# BAT32A237 register map
Vendor: CMS; Series: BAT32A237; File version: 1.2
CPU: CM0+ r0p1, little endian, MPU, no FPU, VTOR, 2 interrupt priority bits
Registers are 8-bit, read-write, reset 0x0 unless marked. A register's access mark holds for its fields unless they carry their own. Offsets are from the block's base; [hi:lo] are bit positions; {n}, {i} and the like mark numbered series.

## MTB — Micro Trace Buffer
Base 0x40019000
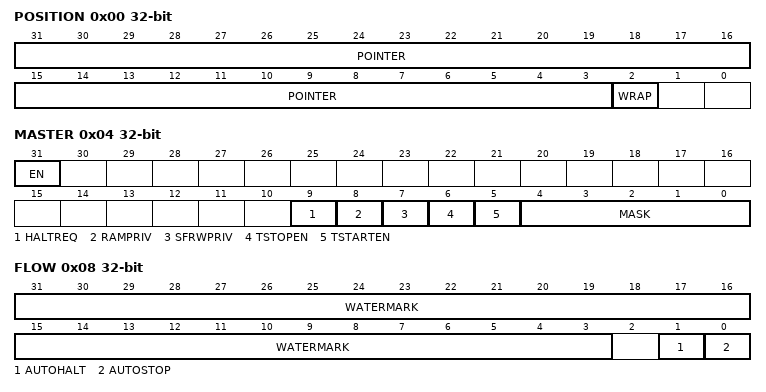
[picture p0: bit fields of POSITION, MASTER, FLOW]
0x00 POSITION 32-bit — MTB Position Register
  [31:3] POINTER, [2] WRAP
0x04 MASTER 32-bit — MTB Master Register
  [31] EN, [9] HALTREQ, [8] RAMPRIV, [7] SFRWPRIV, [6] TSTOPEN, [5] TSTARTEN, [4:0] MASK
0x08 FLOW 32-bit — MTB Flow Register
  [31:3] WATERMARK, [1] AUTOHALT, [0] AUTOSTOP
0x0C BASE 32-bit ro reset 0x20000000 — MTB Base Register
0xFB0 LOCKACCESS 32-bit — MTB Lock Access Register
0xFB4 LOCKSTATUS 32-bit ro — MTB Lock Status Register
0xFB8 AUTHSTATUS 32-bit ro reset 0xF — MTB Authentication Status Register
0xFBC DEVARCH 32-bit ro reset 0x47700A31 — MTB Device Architecture Register
0xFC8 DEVID 32-bit ro — MTB Device Configuration Register
0xFCC DEVTYPE 32-bit ro — MTB Device Type Register
{0xFC0+4i} PID{i} (i=4..7) 32-bit ro — CoreSight Register
{0xFE0+4i} PID{i} (i=0..3) 32-bit ro — CoreSight Register
{0xFF0+4i} CID{i} (i=0..3) 32-bit ro — CoreSight Register

## RST — Reset Function
Base 0x40020420
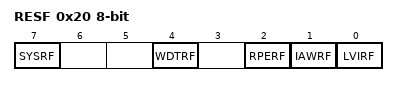
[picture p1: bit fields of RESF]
0x20 RESF ro — Reset flag register
  [all] fields
    0=NONE (Internal reset request is not generated, or the RESF register is cleared.); 1=DONE (Internal reset request is generated.)
  [7] SYSRF read-clears — Internal reset request by system reset request(AIRCR.SYSRESETREQ)
  [4] WDTRF read-clears — Internal reset request by watchdog timer(WDT)
  [2] RPERF read-clears — Internal reset request by RAM parity
  [1] IAWRF read-clears — Internal reset request by illegal-memory access
  [0] LVIRF read-clears — Internal reset request by voltage detector

## LVD — Voltage detector
Base 0x40020440
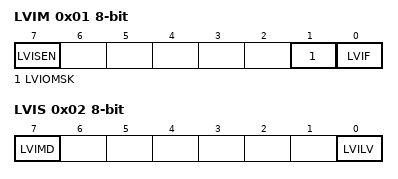
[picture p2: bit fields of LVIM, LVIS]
0x01 LVIM — Voltage detection register
  [7] LVISEN ro — Enable rewritting LVIS register
    0=Disable (Disabling of rewriting the LVIS register); 1=Enable (Enabling of rewriting the LVIS register)
  [1] LVIOMSK ro — Mask status flag of LVD output
    0=Invalid (Mask of LVD output is invalid); 1=Valid (Mask of LVD output is valid)
  [0] LVIF ro — Voltage detection flag
    0=GE (Supply voltage (VDD) greater or equal to detection voltage (VLVD), or when LVD is off); 1=LT (Supply voltage (VDD) less than detection voltage (VLVD))
0x02 LVIS — Voltage detection level register
  [7] LVIMD — Operation mode of voltage detection
    0=IRQ (interrupt mode); 1=reset mode
  [0] LVILV — LVD detection level
    0=High-voltage detection level (VLVDH); 1=Low (Low-voltage detection level (VLVDL or VLVD))

## PORT — Port functions
Base 0x40040000
0x30 PU0 (reset mask 0x7F) — Pull-up resistor option register 0
0x31 PU1 — Pull-up resistor option register 1
0x33 PU3 (reset mask 0x3) — Pull-up resistor option register 3
0x34 PU4 reset 0x1 (reset mask 0xF) — Pull-up resistor option register 4
0x35 PU5 (reset mask 0x3F) — Pull-up resistor option register 5
0x37 PU7 — Pull-up resistor option register 7
0x3C PU12 (reset mask 0x1) — Pull-up resistor option register 12
0x3D PU13 reset 0x80 (reset mask 0xC0) — Pull-up resistor option register 13
0x3E PU14 (reset mask 0xC3) — Pull-up resistor option register 14
0x40 PIM0 (reset mask 0x1B) — Port input mode register 0
0x41 PIM1 (reset mask 0xF1) — Port input mode register 1
0x43 PIM3 (reset mask 0x3) — Port input mode register 3
0x45 PIM5 (reset mask 0x21) — Port input mode register 5
0x47 PIM7 (reset mask 0x14) — Port input mode register 7
0x50 POM0 (reset mask 0x1F) — Port output mode register 0
0x51 POM1 (reset mask 0xBB) — Port output mode register 1
0x53 POM3 (reset mask 0x3) — Port output mode register 3
0x55 POM5 (reset mask 0x23) — Port output mode register 5
0x57 POM7 (reset mask 0x16) — Port output mode register 7
0x60 PMC0 reset 0xFF (reset mask 0xF) — Port mode control register 0
0x61 PMC1 reset 0xFF (reset mask 0x1F) — Port mode control register 1
0x62 PMC2 reset 0xFF — Port mode control register 2
0x6C PMC12 reset 0xFF (reset mask 0x1) — Port mode control register 12
0x6E PMC14 reset 0xFF (reset mask 0x80) — Port mode control register 14
0x300 P0 (reset mask 0x7F) — Port register 0
0x301 P1 — Port register 1
0x302 P2 — Port register 2
0x303 P3 (reset mask 0x3) — Port register 3
0x304 P4 (reset mask 0xF) — Port register 4
0x305 P5 (reset mask 0x3F) — Port register 5
0x306 P6 (reset mask 0xF) — Port register 6
0x307 P7 — Port register 7
0x30C P12 (reset mask 0x1F) — Port register 12
0x30D P13 (reset mask 0xC1) — Port register 13
0x30E P14 (reset mask 0xC3) — Port register 14
0x320 PM0 reset 0xFF (reset mask 0x7F) — Port mode register 0
0x321 PM1 reset 0xFF — Port mode register 1
0x322 PM2 reset 0xFF — Port mode register 2
0x323 PM3 reset 0xFF (reset mask 0x3) — Port mode register 3
0x324 PM4 reset 0xFF (reset mask 0xF) — Port mode register 4
0x325 PM5 reset 0xFF (reset mask 0x3F) — Port mode register 5
0x326 PM6 reset 0xFF (reset mask 0xF) — Port mode register 6
0x327 PM7 reset 0xFF — Port mode register 7
0x32C PM12 reset 0xFF (reset mask 0x1) — Port mode register 12
0x32D PM13 reset 0xFE (reset mask 0xC0) — Port mode register 13
0x32E PM14 reset 0xFF (reset mask 0xC3) — Port mode register 14
0x875 PIOR2 — Peripheral I/O redirection register 2
0x877 PIOR0 — Peripheral I/O redirection register 0
0x879 PIOR1 (reset mask 0xF) — Peripheral I/O redirection register 1
0x87B PMS (reset mask 0x1) — Port mode select register
0x87C PIOR3 (reset mask 0x3F) — Peripheral I/O redirection register 3
0x87D GDIDIS (reset mask 0x1) — Global digital input disable register
